# FM33L0XX register map
File version: 1.0
CPU: SC000 r1p0, little endian, no MPU, no FPU, 3 interrupt priority bits
Registers are 32-bit, read-write, reset 0x0 unless marked. A register's access mark holds for its fields unless they carry their own. Offsets are from the block's base; [hi:lo] are bit positions; {n}, {i} and the like mark numbered series.

## RCC — RESET AND CLOCK CONTROL UNIT
Base 0x40000200
0x00 LKP_CR — Lockup reset Control Register
  [1] RST_EN — LOCKUP reset enable
    0=DISABLE (LOCKUP reset is disable); 1=ENABLE (LOCKUP reset is enable)
0x04 SOFTRST — soft reset Register
  [31:0] SOFTRST — Write softreset key word to reset CPU
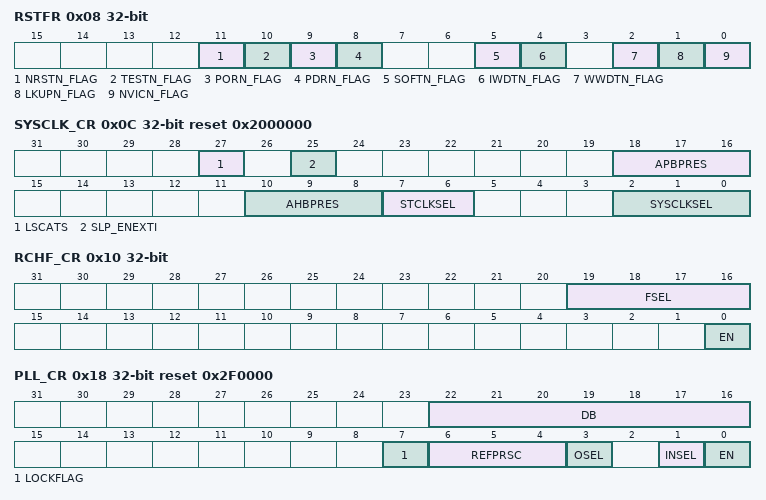
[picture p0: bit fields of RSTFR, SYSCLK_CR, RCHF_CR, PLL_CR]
0x08 RSTFR — RESET FLAG Register
  [11] NRSTN_FLAG — NRST reset flag
    0=NO_NRST (no NRST reset); 1=NRST (NRST reset occurs)
  [10] TESTN_FLAG — TEST reset flag
    0=NO_TEST (no TEST reset); 1=TEST (TEST reset occurs)
  [9] PORN_FLAG — POWER ON reset flag
    0=NO_POR (no POR reset); 1=POR (POR reset occurs)
  [8] PDRN_FLAG — POWER DOWN reset flag
    0=NO_PDR (no PDR reset); 1=PDR (PDR reset occurs)
  [5] SOFTN_FLAG — SOFT reset flag
    0=NO_SOFT (no SOFT reset); 1=SOFT (SOFT reset occurs)
  [4] IWDTN_FLAG — IWDT reset flag
    0=NO_IWDT (no IWDT reset); 1=IWDT (IWDT reset occurs)
  [2] WWDTN_FLAG — WWDT reset flag
    0=NO_WWDT (no WWDT reset); 1=WWDT (WWDT reset occurs)
  [1] LKUPN_FLAG — LOCKUP reset flag
    0=NO_LUCKUP (no LUCKUP reset); 1=LUCKUP (LUCKUP reset occurs)
  [0] NVICN_FLAG — NVIC reset flag
    0=NO_NVIC (no NVIC reset); 1=NVIC (NVIC reset occurs)
0x0C SYSCLK_CR reset 0x2000000 — system clock select Register
  [27] LSCATS — lsclk auto select config
    0=lsclk_change_auto_dis (lsclk auto select disable); 1=lsclk_change_auto_en (lsclk auto select enable)
  [25] SLP_ENEXTI — EXTI sample clk enable bit ,at sleep/deepsleep mode
    0=DISABLE (EXTI sample clk disable); 1=ENABLE (EXTI sample clk enable)
  [18:16] APBPRES — APB clk divide
    {v}=NO_DIV (APB clock is not divided at 0x0xx) (v=0..3); 4=DIV2 (APB clock is divided by 2); 5=DIV4 (APB clock is divided by 4); 6=DIV8 (AHB clock is divided by 8); 7=DIV16 (AHB clock is divided by 16)
  [10:8] AHBPRES — AHB clk divide
    {v}=NO_DIV (AHB clock is not divided at 0x0xx) (v=0..3); 4=DIV2 (AHB clock is divided by 2); 5=DIV4 (AHB clock is divided by 4); 6=DIV8 (AHB clock is divided by 8); 7=DIV16 (AHB clock is divided by 16)
  [7:6] STCLKSEL — systick clock select bit
    0=SCLK (systick clock is sclk); 1=LSCLK (systick clock is lsclk); 2=RC4M (systick clock is rc4m); 3=SYSCLK (systick clock is sysclk)
  [2:0] SYSCLKSEL — System clock select bit
    0=RCHF (system clock source is RCHF); 1=XTHF (system clock source is XHTF); 2=PLL (system clock source is PLL); 3=RCHF (system clock source is RCHF); 4=RC4MPSC (system clock source is RC4MPSC); 5=LSCLK (system clock source is LSCLK); 6=LSCLK (system clock source is LSCLK); 7=LSCLK (system clock source is LSCLK)
0x10 RCHF_CR — RCHF config Register
  [19:16] FSEL — RCHF frequency select
    0=8MHz (RCHF center frequency is 8MHz); 1=16MHz (RCHF center frequency is 16MHz); 2=24MHz (RCHF center frequency is 24MHz)
  [0] EN — RCHF enable bit
    0=DISABLE (RCHF is disable); 1=ENABLE (RCHF is enable)
0x14 RC4M_TR reset 0x40 — RC4M trim Register
  [6:0] TRIM — RC4M trim bit
0x18 PLL_CR reset 0x2F0000 — PLL Config Register
  [22:16] DB — PLL DB
  [7] LOCKFLAG ro
    0=UNLOCK; 1=LOCK
  [6:4] REFPRSC — PLL DIV
    0=NO_DIV; 1=DIV_2; 2=DIV_4; 3=DIV_8; 4=DIV_12; 5=DIV_16; 6=DIV_24; 7=DIV_32
  [3] OSEL — PLL output select
    0=VCO (PLL output is VCO); 1=TWO_VCO (PLL output is two VCO)
  [1] INSEL — PLL input clk source select
    0=RCHF (PLL input clk source is RCHF); 1=XTHF (PLL input clk source is XTHF)
  [0] EN — PLL enable bit
    0=DISABLE (PLL is disable); 1=ENABLE (PLL is enable)
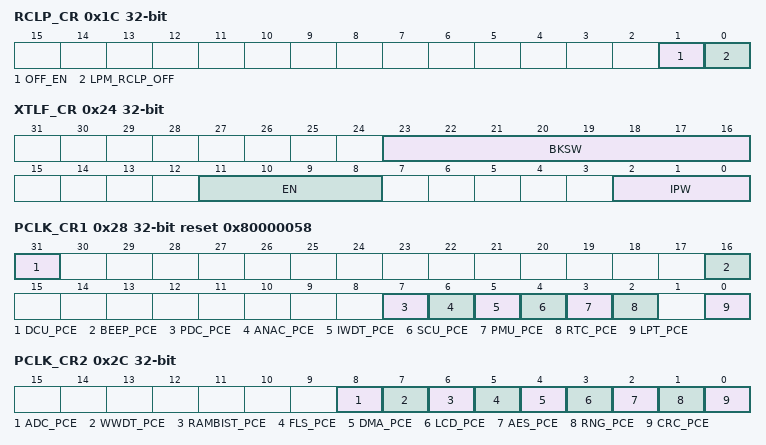
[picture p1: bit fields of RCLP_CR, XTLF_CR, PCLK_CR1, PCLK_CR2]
0x1C RCLP_CR — RCLP config Register
  [1] OFF_EN ro — RCLP enable bit
    0=ENABLE (RCLP is enable); 1=DISABLE (RCLP is disable)
  [0] LPM_RCLP_OFF — sleep_rclp_control
    0=DISABLE (sleep_rclp_off_Disable); 1=ENABLE (sleep_rclp_off_Enable)
0x20 RCLP_TR reset 0x80 — RCLP TRIM Register
  [7:0] RCLP_TR — RCLP TRIM bit
    0=RCLP TRIM_MIN; 255=RCLP TRIM_MAX
0x24 XTLF_CR — XTLF IPW Config Register
  [23:16] BKSW — BKSW bit
  [11:8] EN — XTLFEN bit
    10=DISABLE (XTLF DISABLE); 5=ENABLE (XTLF ENABLE)
  [2:0] IPW — XTLF IPW bit
    0=450 nA (XTLF IPW is 450 nA); 1=400 nA (XTLF IPW is 400 nA); 2=350 nA (XTLF IPW is 350 nA); 3=300 nA (XTLF IPW is 300 nA); 4=250 nA (XTLF IPW is 250 nA); 5=200 nA (XTLF IPW is 200 nA); 6=150 nA (XTLF IPW is 150 nA); 7=100 nA (XTLF IPW is 100 nA)
0x28 PCLK_CR1 reset 0x80000058 — peripheral clk Config Register 1
  [31] DCU_PCE — DCU clk enable
    0=DISABLE (DCU clk is disable); 1=ENABLE (DCU clk is enable)
  [16] BEEP_PCE — BEEP clk enable
    0=DISABLE (BEEP clk is disable); 1=ENABLE (BEEP clk is enable)
  [7] PDC_PCE — PDC clk enable
    0=DISABLE (PDC clk is disable); 1=ENABLE (PDC clk is enable)
  [6] ANAC_PCE — ANAC clk enable
    0=DISABLE (ANAC clk is disable); 1=ENABLE (ANAC clk is enable)
  [5] IWDT_PCE — IWDT clk enable
    0=DISABLE (IWDT clk is disable); 1=ENABLE (IWDT clk is enable)
  [4] SCU_PCE — SCU clk enable
    0=DISABLE (SCU clk is disable); 1=ENABLE (SCU clk is enable)
  [3] PMU_PCE — PMU clk enable
    0=DISABLE (PMU clk is disable); 1=ENABLE (PMU clk is enable)
  [2] RTC_PCE — RTC clk enable
    0=DISABLE (RTC clk is disable); 1=ENABLE (RTC clk is enable)
  [0] LPT_PCE — LPTIM reg clk enable
    0=DISABLE (LPTIM reg clk is disable); 1=ENABLE (LPTIM reg clk is enable)
0x2C PCLK_CR2 — peripheral clk Config Register 2
  [8] ADC_PCE — ADC clk enable
    0=DISABLE (ADC clk is disable); 1=ENABLE (ADC clk is enable)
  [7] WWDT_PCE — WWDT clk enable
    0=DISABLE (WWDT clk is disable); 1=ENABLE (WWDT clk is enable)
  [6] RAMBIST_PCE — RAMBIST clk enable
    0=DISABLE (RAMBIST clk is disable); 1=ENABLE (RAMBIST clk is enable)
  [5] FLS_PCE — FLASH clk enable
    0=DISABLE (FLASH clk is disable); 1=ENABLE (FLASH clk is enable)
  [4] DMA_PCE — DMA clk enable
    0=DISABLE (DMA clk is disable); 1=ENABLE (DMA clk is enable)
  [3] LCD_PCE — LCD clk enable
    0=DISABLE (LCD clk is disable); 1=ENABLE (LCD clk is enable)
  [2] AES_PCE — AES clk enable
    0=DISABLE (AES clk is disable); 1=ENABLE (AES clk is enable)
  [1] RNG_PCE — RNG clk enable
    0=DISABLE (RNG clk is disable); 1=ENABLE (RNG clk is enable)
  [0] CRC_PCE — CRC clk enable
    0=DISABLE (CRC clk is disable); 1=ENABLE (CRC clk is enable)
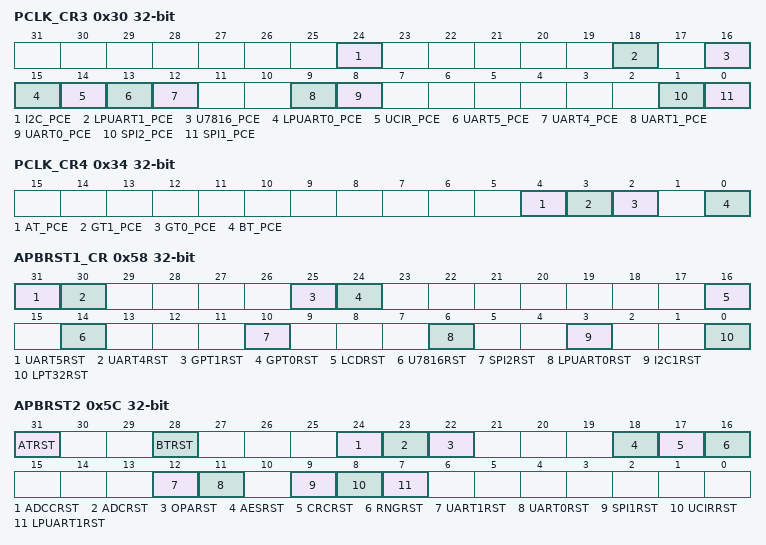
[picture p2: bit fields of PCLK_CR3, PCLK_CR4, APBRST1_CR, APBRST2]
0x30 PCLK_CR3 — peripheral clk Config Register 3
  [24] I2C_PCE — I2C clk enable
    0=DISABLE (I2C clk is disable); 1=ENABLE (I2C clk is enable)
  [18] LPUART1_PCE — LPUART1 clk enable
    0=DISABLE (LPUART1 clk is disable); 1=ENABLE (LPUART1 clk is enable)
  [16] U7816_PCE — U7816 clk enable
    0=DISABLE (U7816 clk is disable); 1=ENABLE (U7816 clk is enable)
  [15] LPUART0_PCE — LPUART0 clk select
    0=DISABLE (LPUART0 clk is disable); 1=ENABLE (LPUART clk is enable)
  [14] UCIR_PCE — UCIR clk enable
    0=DISABLE (UCIR clk is disable); 1=ENABLE (UCIR clk is enable)
  [13] UART5_PCE — UART5 clk enable
    0=DISABLE (UART5 clk is disable); 1=ENABLE (UART5 clk is enable)
  [12] UART4_PCE — UART4 clk enable
    0=DISABLE (UART4 clk is disable); 1=ENABLE (UART4 clk is enable)
  [9] UART1_PCE — UART1 clk enable
    0=DISABLE (UART1 clk is disable); 1=ENABLE (UART1 clk is enable)
  [8] UART0_PCE — UART0 clk enable
    0=DISABLE (UART0 clk is disable); 1=ENABLE (UART0 clk is enable)
  [1] SPI2_PCE — SPI2 clk enable
    0=DISABLE (SPI2 clk is disable); 1=ENABLE (SPI2 clk is enable)
  [0] SPI1_PCE — SPI1 clk enable
    0=DISABLE (SPI clk is disable); 1=ENABLE (SPI clk is enable)
0x34 PCLK_CR4 — peripheral clk Config Register 4
  [4] AT_PCE — ATimer clk enable
    0=DISABLE (AT clk is disable); 1=ENABLE (AT clk is enable)
  [3] GT1_PCE — GTimer1 clk enable
    0=DISABLE (GT1 clk is disable); 1=ENABLE (GT1 clk is enable)
  [2] GT0_PCE — GTimer0 clk enable
    0=DISABLE (GT0 clk is disable); 1=ENABLE (GT0 clk is enable)
  [0] BT_PCE — BT clk enable
    0=DISABLE (BT clk is disable); 1=ENABLE (BT clk is enable)
0x44 AHMB_CR — AHB master priority
  [0] MPRIL
    0=DMA (DMA is high priority); 1=CPU (CPU is high priority)
0x50 PERHRSTEN write
0x54 AHBRST_CR
  [0] DMARST — DMARST_EN
    0=DISABLE (DMA_RST_DISABLE); 1=ENABLE (DMA_RST_ENABLE)
0x58 APBRST1_CR
  [31] UART5RST — UART5RST_EN
    0=DISABLE (UART5RST_DISABLE); 1=ENABLE (UART5RST_ENABLE)
  [30] UART4RST — UART4RST_EN
    0=DISABLE (UART4RST_DISABLE); 1=ENABLE (UART4RST_ENABLE)
  [25] GPT1RST — GPT1RST_EN
    0=DISABLE (GPT1RST_DISABLE); 1=ENABLE (GPT1RST_ENABLE)
  [24] GPT0RST — GPT0RST_EN
    0=DISABLE (GPT0RST_DISABLE); 1=ENABLE (GPT0RST_ENABLE)
  [16] LCDRST — LCDRST_EN
    0=DISABLE (LCDRST_DISABLE); 1=ENABLE (LCDRST_ENABLE)
  [14] U7816RST — U7816RST_EN
    0=DISABLE (U7816RST_DISABLE); 1=ENABLE (U7816RST_ENABLE)
  [10] SPI2RST — SPI2RST_EN
    0=DISABLE (SPI2RST_DISABLE); 1=ENABLE (SPI2RST_ENABLE)
  [6] LPUART0RST — LPUART0RST_EN
    0=DISABLE (LPUART0RST_DISABLE); 1=ENABLE (LPUART0RST_ENABLE)
  [3] I2C1RST — I2C1RST_EN
    0=DISABLE (I2C1RST_DISABLE); 1=ENABLE (I2C1RST_ENABLE)
  [0] LPT32RST — LPT32RST_EN
    0=DISABLE (LPT32RST_DISABLE); 1=ENABLE (LPT32RST_ENABLE)
0x5C APBRST2
  [31] ATRST — ATRST_EN
    0=DISABLE (ATRST_DISABLE); 1=ENABLE (ATRST_ENABLE)
  [28] BTRST — BTRST_EN
    0=DISABLE (BTRST_DISABLE); 1=ENABLE (BTRST_ENABLE)
  [24] ADCCRST — ADCCRST_EN
    0=DISABLE (ADCCRST_DISABLE); 1=ENABLE (ADCCRST_ENABLE)
  [23] ADCRST — ADCRST_EN
    0=DISABLE (ADCRST_DISABLE); 1=ENABLE (ADCRST_ENABLE)
  [22] OPARST — OPARST_EN
    0=DISABLE (OPARST_DISABLE); 1=ENABLE (OPARST_ENABLE)
  [18] AESRST — AESRST_EN
    0=DISABLE (AESRST_DISABLE); 1=ENABLE (AESRST_ENABLE)
  [17] CRCRST — CRCRST_EN
    0=DISABLE (CRCRST_DISABLE); 1=ENABLE (CRCRST_ENABLE)
  [16] RNGRST — RNGRST_EN
    0=DISABLE (RNGRST_DISABLE); 1=ENABLE (RNGRST_ENABLE)
  [12] UART1RST — UART1RST_EN
    0=DISABLE (UART1RST_DISABLE); 1=ENABLE (UART1RST_ENABLE)
  [11] UART0RST — UART0RST_EN
    0=DISABLE (UART0RST_DISABLE); 1=ENABLE (UART0RST_ENABLE)
  [9] SPI1RST — SPI1RST_EN
    0=DISABLE (SPI1RST_DISABLE); 1=ENABLE (SPI1RST_ENABLE)
  [8] UCIRRST — UCIRRST_EN
    0=DISABLE (UCIRRST_DISABLE); 1=ENABLE (UCIRRST_ENABLE)
  [7] LPUART1RST — LPUART1RST_EN
    0=DISABLE (LPUART1RST_DISABLE); 1=ENABLE (LPUART1RST_ENABLE)
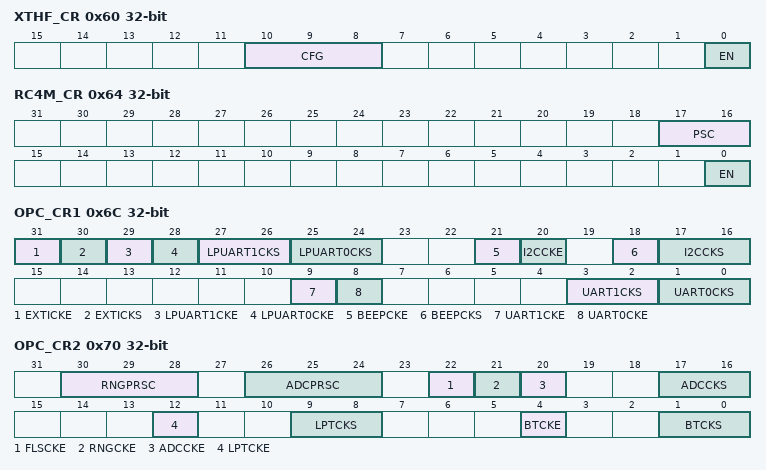
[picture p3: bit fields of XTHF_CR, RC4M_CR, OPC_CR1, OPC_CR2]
0x60 XTHF_CR
  [10:8] CFG — XTHF_CONFIG
    0=XTHF_weak_config; 7=XTHF_strong_config
  [0] EN — XTHF_EN
    0=DISABLE (XTHF_DISABLE); 1=ENABLE (XTHF_ENABLE)
0x64 RC4M_CR
  [17:16] PSC — RC4M_PSC
    0=NO_DIV (RC4M_NO_DIV); 1=DIV_4 (RC4M_DIV_4); 2=DIV_8 (RC4M_DIV_8); 3=DIV_16 (RC4M_DIV_16)
  [0] EN — RC4M_EN
    0=DISABLE (RC4M_DISABLE); 1=ENABLE (RC4M_ENABLE)
0x68 RCHF_TR reset 0x80 — RCHFTRIM
  [6:0] TRIM — RCHF_TRIM
0x6C OPC_CR1
  [31] EXTICKE — EXTI clock en
    0=DISABLE (EXTI clock DISABLE); 1=ENABLE (EXTI clock ENABLE)
  [30] EXTICKS — EXTI clock select
    0=HCLK (EXTI clock select HCLK); 1=LSCLK (EXTI clock select LSCLK)
  [29] LPUART1CKE — LPUART1 clock en
    0=DISABLE (LPUART1 clock DISABLE); 1=ENABLE (LPUART1 clock ENABLE)
  [28] LPUART0CKE — LPUART0 clock en
    0=DISABLE (LPUART0 clock DISABLE); 1=ENABLE (LPUART0 clock ENABLE)
  [27:26] LPUART1CKS — LPUART1 clock select
    0=LSCLK (LPUART1 clock select LSCLK); 1=RCHF_DIV (LPUART1 clock select RCHF_DIV); 2=RC4M_DIV (LPUART1 clock select RC4M_DIV)
  [25:24] LPUART0CKS — LPUART0 clock select
    0=LSCLK (LPUART0 clock select LSCLK); 1=RCHF_DIV (LPUART0 clock select RCHF_DIV); 2=RC4M_DIV (LPUART0 clock select RC4M_DIV)
  [21] BEEPCKE — BEEP clock en
    0=DISABLE (BEEP clock DISABLE); 1=ENABLE (BEEP clock ENABLE)
  [20] I2CCKE — I2C clock en
    0=DISABLE (I2C clock DISABLE); 1=ENABLE (I2C clock ENABLE)
  [18] BEEPCKS — BEEP clock select
    0=XTLF (BEEP clock select APBCLK); 1=RCLP (BEEP clock select RCHF)
  [17:16] I2CCKS — I2C clock select
    0=APBCLK (I2C clock select APBCLK); 1=RCHF (I2C clock select RCHF); 2=SYSCLK (I2C clock select SYSCLK); 3=RC4M_PSC (I2C clock select RC4M_PSC)
  [9] UART1CKE — UART1 clock en
    0=DISABLE (UART1 clock DISABLE); 1=ENABLE (UART1 clock ENABLE)
  [8] UART0CKE — UART0 clock en
    0=DISABLE (UART0 clock DISABLE); 1=ENABLE (UART0 clock ENABLE)
  [3:2] UART1CKS — UART1 clock select
    0=APBCLK (UART1 clock select APBCLK); 1=RCHF (UART1 clock select RCHF); 2=SYSCLK (UART1 clock select SYSCLK); 3=RC4M_PSC (UART1 clock select RC4M_PSC)
  [1:0] UART0CKS — UART0 clock select
    0=APBCLK (UART0 clock select APBCLK); 1=RCHF (UART0 clock select RCHF); 2=SYSCLK (UART0 clock select SYSCLK); 3=RC4M_PSC (UART0 clock select RC4M_PSC)
0x70 OPC_CR2
  [30:28] RNGPRSC — RNG clock psc
    0=NO_DIV (RNG clock NO_DIV); 1=DIV_2 (RNG clock DIV_2); 2=DIV_4 (RNG clock DIV_4); 3=DIV_8 (RNG clock DIV_8); 4=DIV_16 (RNG clock DIV_16); 5=DIV_32 (RNG clock DIV_32)
  [26:24] ADCPRSC — ADC clock psc
    0=NO_DIV (ADC clock NO_DIV); 1=DIV_2 (ADC clock DIV_2); 2=DIV_4 (ADC clock DIV_4); 3=DIV_8 (ADC clock DIV_8); 4=DIV_16 (ADC clock DIV_16); 5=DIV_32 (ADC clock DIV_32)
  [22] FLSCKE — FLS clock en
    0=DISABLE (NVM clock DISABLE); 1=ENABLE (NVM clock ENABLE)
  [21] RNGCKE — RNG clock en
    0=DISABLE (RNG clock DISABLE); 1=ENABLE (RNG clock ENABLE)
  [20] ADCCKE — ADC clock en
    0=DISABLE (ADC clock DISABLE); 1=ENABLE (ADC clock ENABLE)
  [17:16] ADCCKS — ADC clock select
    0=RC4M_PSC (ADC clock select RC4M_PSC); 1=RCHF (ADC clock select RCHF); 2=XTHF (ADC clock select XTHF); 3=PLL (ADC clock select PLL)
  [12] LPTCKE — LPT clock en
    0=DISABLE (LPT clock DISABLE); 1=ENABLE (LPT clock ENABLE)
  [9:8] LPTCKS — LPT clock select
    0=APBCLK (LPT clock select APBCLK); 1=LSCLK (LPT clock select LSCLK); 2=RCLP (LPT clock select RCLP); 3=RC4M_PSC (LPT clock select RC4M_PSC)
  [4] BTCKE — BT clock en
    0=DISABLE (BT clock DISABLE); 1=ENABLE (BT clock ENABLE)
  [1:0] BTCKS — BT clock select
    0=APBCLK (BT clock select APBCLK); 1=LSCLK (BT clock select LSCLK); 2=RCLP (BT clock select RCLP); 3=RC4M_PSC (BT clock select RC4M_PSC)
